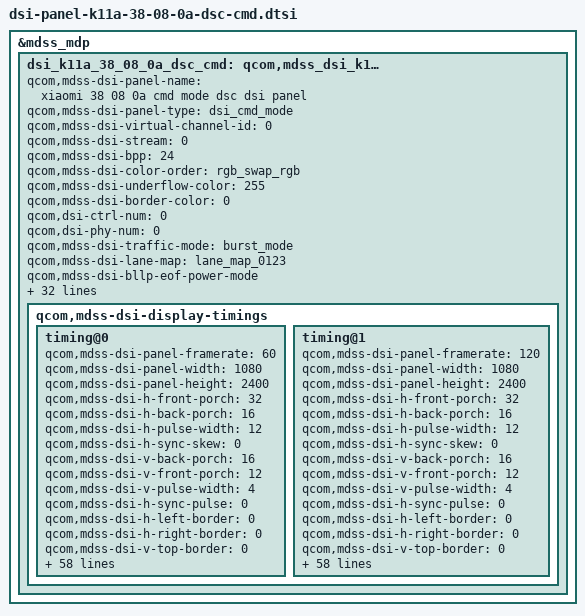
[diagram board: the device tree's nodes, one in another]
&mdss_mdp {
	dsi_k11a_38_08_0a_dsc_cmd: qcom,mdss_dsi_k11a_38_08_0a_dsc_cmd {
		qcom,mdss-dsi-panel-name = "xiaomi 38 08 0a cmd mode dsc dsi panel";
		qcom,mdss-dsi-panel-type = "dsi_cmd_mode";
		qcom,mdss-dsi-virtual-channel-id = <0>;
		qcom,mdss-dsi-stream = <0>;
		qcom,mdss-dsi-bpp = <24>;
		qcom,mdss-dsi-color-order = "rgb_swap_rgb";
		qcom,mdss-dsi-underflow-color = <255>;
		qcom,mdss-dsi-border-color = <0>;

		qcom,dsi-ctrl-num = <0>;
		qcom,dsi-phy-num = <0>;

		qcom,mdss-dsi-traffic-mode = "burst_mode";
		qcom,mdss-dsi-lane-map = "lane_map_0123";
		qcom,mdss-dsi-bllp-eof-power-mode;
		qcom,mdss-dsi-bllp-power-mode;
		qcom,mdss-dsi-lane-0-state;
		qcom,mdss-dsi-lane-1-state;
		qcom,mdss-dsi-lane-2-state;
		qcom,mdss-dsi-lane-3-state;
		qcom,mdss-dsi-dma-trigger = "trigger_sw";
		qcom,mdss-dsi-mdp-trigger = "none";
		qcom,mdss-dsi-reset-sequence = <0 10>, <1 10>;
		qcom,mdss-pan-physical-width-dimension = <70>;
		qcom,mdss-pan-physical-height-dimension = <155>;
		qcom,mdss-dsi-te-pin-select = <1>;
		qcom,mdss-dsi-wr-mem-start = <44>;
		qcom,mdss-dsi-wr-mem-continue = <60>;
		qcom,mdss-dsi-te-dcs-command = <1>;
		qcom,mdss-dsi-te-check-enable;
		qcom,mdss-dsi-te-using-te-pin;
		qcom,mdss-dsi-tx-eot-append;
		qcom,mdss-dsi-lp11-init;

		qcom,mdss-dsi-panel-hdr-enabled;
		qcom,mdss-dsi-panel-hdr-color-primaries = <14500 15500 32000
			17000 15500 30000 8000 3000>;
		qcom,mdss-dsi-panel-peak-brightness = <4200000>;
		qcom,mdss-dsi-panel-blackness-level = <3230>;

		qcom,bl-update-flag = "delay_until_first_frame";

		qcom,mdss-dsi-display-timings {
			timing@0 {
				qcom,mdss-dsi-panel-framerate = <60>;
				qcom,mdss-dsi-panel-width = <1080>;
				qcom,mdss-dsi-panel-height = <2400>;
				qcom,mdss-dsi-h-front-porch = <32>;
				qcom,mdss-dsi-h-back-porch = <16>;
				qcom,mdss-dsi-h-pulse-width = <12>;
				qcom,mdss-dsi-h-sync-skew = <0>;
				qcom,mdss-dsi-v-back-porch = <16>;
				qcom,mdss-dsi-v-front-porch = <12>;
				qcom,mdss-dsi-v-pulse-width = <4>;
				qcom,mdss-dsi-h-sync-pulse = <0>;
				qcom,mdss-dsi-h-left-border = <0>;
				qcom,mdss-dsi-h-right-border = <0>;
				qcom,mdss-dsi-v-top-border = <0>;
				qcom,mdss-dsi-v-bottom-border = <0>;
				qcom,mdss-dsi-panel-clockrate = <1100000000>;
				qcom,mdss-dsi-panel-jitter = <5 1>;
				qcom,mdss-mdp-transfer-time-us = <14000>;
				qcom,mdss-dsi-on-command = [
					39 01 00 00 00 00 02 9D 01 05 01
					00 00 0A 00 01 11 15 01
					00 00 00 00 02 60 00 15 01
					00 00 00 00 02 35 00 39 01
					00 00 00 00 03 F0 5A 5A
					39 01 00 00 00 00 03 F1 5A 5A
					39 01 00 00 00 00 03 FC 5A 5A
					39 01 00 00 00 00 04 E5 13 E8 FC
					39 01 00 00 00 00 02 ED 97
					39 01 00 00 00 00 02 B0 1A
					39 01 00 00 00 00 02 F9 20 15 01
					00 00 00 00 02 B0 02 15 01
					00 00 00 00 02 F8 C4 15 01
					00 00 00 00 02 B0 04 39 01
					00 00 00 00 06 F8 41 45 22 2C 2C 15 01
					00 00 00 00 02 B0 02 15 01
					00 00 00 00 02 F8 CC 15 01
					00 00 00 00 02 55 00 39 01
					00 00 00 00 29 BD 00 FF FF 09 15
					00 73 18 00 00 09 15 43 92
					00 44 44 00 09 15 43 92 00 22 22 09 15 43 92
					00 11 11 00 09 15 43 92
					00 00 00 15 01 00 00 00
					00 02 8B 00 39 01 00 00
					00 00 03 81 31 02 15 01
					00 00 00 00 02 B0 2B 39 01
					00 00 00 00 16 B1 E4 05
					00 07 E0 01 0C 02 F0 18 FA E3 FB 0A DF F9 F5 01 FF FF FF
					15 01 00 00 00 00 02 B1 00
					39 01 00 00 00 00 03 B0 05 B1
					15 01 00 00 00 00 02 B1 08
					15 01 00 00 00 00 02 B0 05 39 01
					00 00 00 00 04 D7 07 02 40
					15 01 00 00 00 00 02 F5 85
					15 01 00 00 00 00 02 B0 01
					15 01 00 00 00 00 02 F5 77
					15 01 00 00 00 00 02 B0 03
					39 01 00 00 00 00 05 F5 10 40 10 40
					15 01 00 00 00 00 02 68 21
					15 01 00 00 00 00 02 69 01
					39 01 00 00 00 00 03 97 02 60 39 01
					00 00 00 00 03 F0 A5 A5 39 01
					00 00 00 00 03 F1 A5 A5 39 01
					00 00 00 00 03 FC A5 A5 15 01
					00 00 6E 00 02 53 28 05 01
					00 00 00 00 01 29
				];
				qcom,mdss-dsi-off-command = [
					05 01 00 00 14 00 01 28
					15 01 00 00 00 00 02 53
					20 05 01 00 00 78 00 01 10
				];
				qcom,mdss-dsi-on-command-state = "dsi_lp_mode";
				qcom,mdss-dsi-off-command-state = "dsi_lp_mode";

				qcom,mdss-dsi-timing-switch-command = [15 01 00 00 00 00 02 60 00];
				qcom,mdss-dsi-timing-switch-command-state = "dsi_lp_mode";

				qcom,mdss-dsi-lp1-command = [
					05 01 00 00 00 00 01 28
					39 01 00 00 00 00 03 F0 5A 5A
					15 01 00 00 01 00 02 53 22
					39 01 00 00 11 00 03 F0 A5 A5
				];
				qcom,mdss-dsi-nolp-command = [
					05 01 00 00 00 00 01 28
					39 01 00 00 00 00 03 F0 5A 5A
					15 01 00 00 00 00 02 60 00
					15 01 00 00 01 00 02 53 28
					39 01 00 00 22 00 03 F0 A5 A5 05 01
					00 00 00 00 01 29
				];
				qcom,mdss-dsi-nolp-command-state = "dsi_lp_mode";

				qcom,compression-mode = "dsc";
				qcom,mdss-dsc-slice-height = <8>;
				qcom,mdss-dsc-slice-width = <540>;
				qcom,mdss-dsc-slice-per-pkt = <2>;
				qcom,mdss-dsc-bit-per-component = <8>;
				qcom,mdss-dsc-bit-per-pixel = <8>;
				qcom,mdss-dsc-block-prediction-enable;
			};

			timing@1 {
				qcom,mdss-dsi-panel-framerate = <120>;
				qcom,mdss-dsi-panel-width = <1080>;
				qcom,mdss-dsi-panel-height = <2400>;
				qcom,mdss-dsi-h-front-porch = <32>;
				qcom,mdss-dsi-h-back-porch = <16>;
				qcom,mdss-dsi-h-pulse-width = <12>;
				qcom,mdss-dsi-h-sync-skew = <0>;
				qcom,mdss-dsi-v-back-porch = <16>;
				qcom,mdss-dsi-v-front-porch = <12>;
				qcom,mdss-dsi-v-pulse-width = <4>;
				qcom,mdss-dsi-h-sync-pulse = <0>;
				qcom,mdss-dsi-h-left-border = <0>;
				qcom,mdss-dsi-h-right-border = <0>;
				qcom,mdss-dsi-v-top-border = <0>;
				qcom,mdss-dsi-v-bottom-border = <0>;
				qcom,mdss-dsi-panel-clockrate = <1100000000>;
				qcom,mdss-dsi-panel-jitter = <5 1>;
				qcom,mdss-mdp-transfer-time-us = <9000>;
				qcom,mdss-dsi-on-command = [
					39 01 00 00 00 00 02 9D 01 05 01
					00 00 0A 00 01 11 15 01 00
					00 00 00 02 60 10 15 01 00
					00 00 00 02 35 00 39 01 00
					00 00 00 03 F0 5A 5A 39 01
					00 00 00 00 03 F1 5A 5A
					39 01 00 00 00 00 03 FC 5A 5A
					39 01 00 00 00 00 04 E5 13 E8 FC
					39 01 00 00 00 00 02 ED 97
					39 01 00 00 00 00 02 B0 1A
					39 01 00 00 00 00 02 F9 20
					15 01 00 00 00 00 02 B0 02
					15 01 00 00 00 00 02 F8 C4
					15 01 00 00 00 00 02 B0 04
					39 01 00 00 00 00 06 F8 41 45 22 2C 2C
					15 01 00 00 00 00 02 B0 02
					15 01 00 00 00 00 02 F8 CC
					15 01 00 00 00 00 02 55 00
					39 01 00 00 00 00 29 BD 00 FF FF 09
					15 00 73 18 00 00 09 15 43 92
					00 44 44 00 09 15 43 92 00 22 22 09
					15 43 92 00 11 11 00 09 15 43 92
					00 00 00 15 01 00 00 00 00 02 8B 00
					39 01 00 00 00 00 03 81 31 02 15 01
					00 00 00 00 02 B0 2B 39 01
					00 00 00 00 16 B1 E4 05
					00 07 E0 01 0C 02 F0 18 FA E3 FB 0A DF F9 F5 01 FF FF FF
					15 01 00 00 00 00 02 B1 00
					39 01 00 00 00 00 03 B0 05 B1
					15 01 00 00 00 00 02 B1 08
					15 01 00 00 00 00 02 B0 05
					39 01 00 00 00 00 04 D7 07 02 40
					15 01 00 00 00 00 02 F5 85
					15 01 00 00 00 00 02 B0 01
					15 01 00 00 00 00 02 F5 77
					15 01 00 00 00 00 02 B0 03
					39 01 00 00 00 00 05 F5 10 40 10 40
					15 01 00 00 00 00 02 68 21 15 01
					00 00 00 00 02 69 01 39 01
					00 00 00 00 03 97 02 60
					39 01 00 00 00 00 03 F0 A5 A5
					39 01 00 00 00 00 03 F1 A5 A5
					39 01 00 00 00 00 03 FC A5 A5
					15 01 00 00 6E 00 02 53 28 05 01
					00 00 00 00 01 29
				];
				qcom,mdss-dsi-off-command = [
					05 01 00 00 14 00 01 28
					15 01 00 00 00 00 02 53 20 05 01
					00 00 78 00 01 10
				];
				qcom,mdss-dsi-on-command-state = "dsi_lp_mode";
				qcom,mdss-dsi-off-command-state = "dsi_lp_mode";

				qcom,mdss-dsi-timing-switch-command = [15 01 00 00 00 00 02 60 10];
				qcom,mdss-dsi-timing-switch-command-state = "dsi_lp_mode";

				qcom,mdss-dsi-lp1-command = [
					05 01 00 00 00 00 01 28
					39 01 00 00 00 00 03 F0 5A 5A
					15 01 00 00 01 00 02 53 22
					39 01 00 00 11 00 03 F0 A5 A5
				];
				qcom,mdss-dsi-nolp-command = [
					05 01 00 00 00 00 01 28
					39 01 00 00 00 00 03 F0 5A 5A
					15 01 00 00 00 00 02 60 10
					15 01 00 00 01 00 02 53 28
					39 01 00 00 22 00 03 F0 A5 A5 05 01
					00 00 00 00 01 29
				];
				qcom,mdss-dsi-nolp-command-state = "dsi_lp_mode";

				qcom,compression-mode = "dsc";
				qcom,mdss-dsc-slice-height = <8>;
				qcom,mdss-dsc-slice-width = <540>;
				qcom,mdss-dsc-slice-per-pkt = <2>;
				qcom,mdss-dsc-bit-per-component = <8>;
				qcom,mdss-dsc-bit-per-pixel = <8>;
				qcom,mdss-dsc-block-prediction-enable;
			};
		};
	};
};

&dsi_k11a_38_08_0a_dsc_cmd {
	mi,mdss-dsi-bl-dcs-big-endian-type;
	mi,feature-enabled;
	mi,mdss-dsi-panel-hbm-51-ctrl-flag;
	mi,mdss-dsi-panel-hbm-off-51-index = <1>;
	mi,esd-err-irq-gpio = <&tlmm 51 0x2002>;
	mi,mdss-panel-on-dimming-delay = <120>;
	mi,mdss-dsi-panel-hbm-brightness = <1>;
	mi,mdss-dsi-panel-dc-threshold = <440>;
	qcom,mdss-dsi-display-timings {
		timing@0 {
			mi,mdss-dsi-dimmingon-command = [15 01 00 00 00 00 02 53 28];
			mi,mdss-dsi-dimmingon-command-state = "dsi_hs_mode";
			mi,mdss-dsi-dimmingoff-command = [15 01 00 00 00 00 02 53 20];
			mi,mdss-dsi-dimmingoff-command-state = "dsi_hs_mode";

			mi,mdss-dsi-hbm-on-command = [
				15 01 00 00 00 00 02 53 E8
				39 01 00 00 00 00 03 51 00 00
			];
			mi,mdss-dsi-hbm-off-command = [
				15 01 00 00 00 00 02 53 28
				39 01 00 00 00 00 03 51 07 FF
			];
			mi,mdss-dsi-hbm-on-command-state = "dsi_lp_mode";
			mi,mdss-dsi-hbm-off-command-state = "dsi_lp_mode";

			mi,mdss-dsi-doze-hbm-command = [
				39 00 00 00 00 00 03 F0 5A 5A
				15 00 00 00 00 00 02 60 10 15
				00 00 00 01 00 02 53 22 39 01
				00 00 22 00 03 F0 A5 A5
			];
			mi,mdss-dsi-doze-lbm-command = [
				39 00 00 00 00 00 03 F0 5A 5A
				15 00 00 00 00 00 02 60 10
				15 00 00 00 01 00 02 53 23
				39 01 00 00 22 00 03 F0 A5 A5
			];
			mi,mdss-dsi-doze-hbm-command-state = "dsi_lp_mode";
			mi,mdss-dsi-doze-lbm-command-state = "dsi_lp_mode";

			mi,mdss-dsi-flat-on-command = [
				39 00 00 00 00 00 03 F0 5A 5A
				39 00 00 00 00 00 03 C2 2D 27
				15 00 00 00 00 00 02 F7 03
				39 01 00 00 09 00 03 F0 A5 A5
			];
			mi,mdss-dsi-flat-off-command = [
				39 00 00 00 00 00 03 F0 5A 5A
				39 00 00 00 00 00 03 C2 2D 07
				15 00 00 00 00 00 02 F7 03
				39 01 00 00 09 00 03 F0 A5 A5
			];
			mi,mdss-dsi-flat-on-command-state = "dsi_lp_mode";
			mi,mdss-dsi-flat-off-command-state = "dsi_lp_mode";

			mi,mdss-dsi-crc-off-command = [
				/* CRC Disable (Normal mode) */
				39 01 00 00 00 00 02 81 00
				39 00 00 00 00 00 03 F0 5A 5A
				/* CRC Bypass */
				39 00 00 00 00 00 02 B1 01
				39 01 00 00 00 00 03 F0 A5 A5
			];
			mi,mdss-dsi-crc-off-command-state = "dsi_hs_mode";
		};

		timing@1 {
			mi,mdss-dsi-dimmingon-command = [15 01 00 00 00 00 02 53 28];
			mi,mdss-dsi-dimmingon-command-state = "dsi_hs_mode";
			mi,mdss-dsi-dimmingoff-command = [15 01 00 00 00 00 02 53 20];
			mi,mdss-dsi-dimmingoff-command-state = "dsi_hs_mode";

			mi,mdss-dsi-hbm-on-command = [
				15 01 00 00 00 00 02 53 E8
				39 01 00 00 00 00 03 51 00 00
			];
			mi,mdss-dsi-hbm-off-command = [
				15 01 00 00 00 00 02 53 28
				39 01 00 00 00 00 03 51 07 FF
			];
			mi,mdss-dsi-hbm-on-command-state = "dsi_lp_mode";
			mi,mdss-dsi-hbm-off-command-state = "dsi_lp_mode";

			mi,mdss-dsi-doze-hbm-command = [
				39 00 00 00 00 00 03 F0 5A 5A 15
				00 00 00 00 00 02 60 00 15
				00 00 00 01 00 02 53 22
				39 01 00 00 22 00 03 F0 A5 A5
			];
			mi,mdss-dsi-doze-lbm-command = [
				39 00 00 00 00 00 03 F0 5A 5A 15
				00 00 00 00 00 02 60 00 15
				00 00 00 01 00 02 53 23
				39 01 00 00 22 00 03 F0 A5 A5
			];
			mi,mdss-dsi-doze-hbm-command-state = "dsi_lp_mode";
			mi,mdss-dsi-doze-lbm-command-state = "dsi_lp_mode";

			mi,mdss-dsi-flat-on-command = [
				39 00 00 00 00 00 03 F0 5A 5A
				39 00 00 00 00 00 03 C2 2D 27 15
				00 00 00 00 00 02 F7 03
				39 01 00 00 09 00 03 F0 A5 A5
			];
			mi,mdss-dsi-flat-off-command = [
				39 00 00 00 00 00 03 F0 5A 5A
				39 00 00 00 00 00 03 C2 2D 07 15
				00 00 00 00 00 02 F7 03
				39 01 00 00 09 00 03 F0 A5 A5
			];
			mi,mdss-dsi-flat-on-command-state = "dsi_lp_mode";
			mi,mdss-dsi-flat-off-command-state = "dsi_lp_mode";

			mi,mdss-dsi-crc-off-command = [
				/* CRC Disable (Normal mode) */
				39 01 00 00 00 00 02 81 00
				39 00 00 00 00 00 03 F0 5A 5A
				/* CRC Bypass */
				39 00 00 00 00 00 02 B1 01
				39 01 00 00 00 00 03 F0 A5 A5
			];
			mi,mdss-dsi-crc-off-command-state = "dsi_hs_mode";
		};
	};
};
